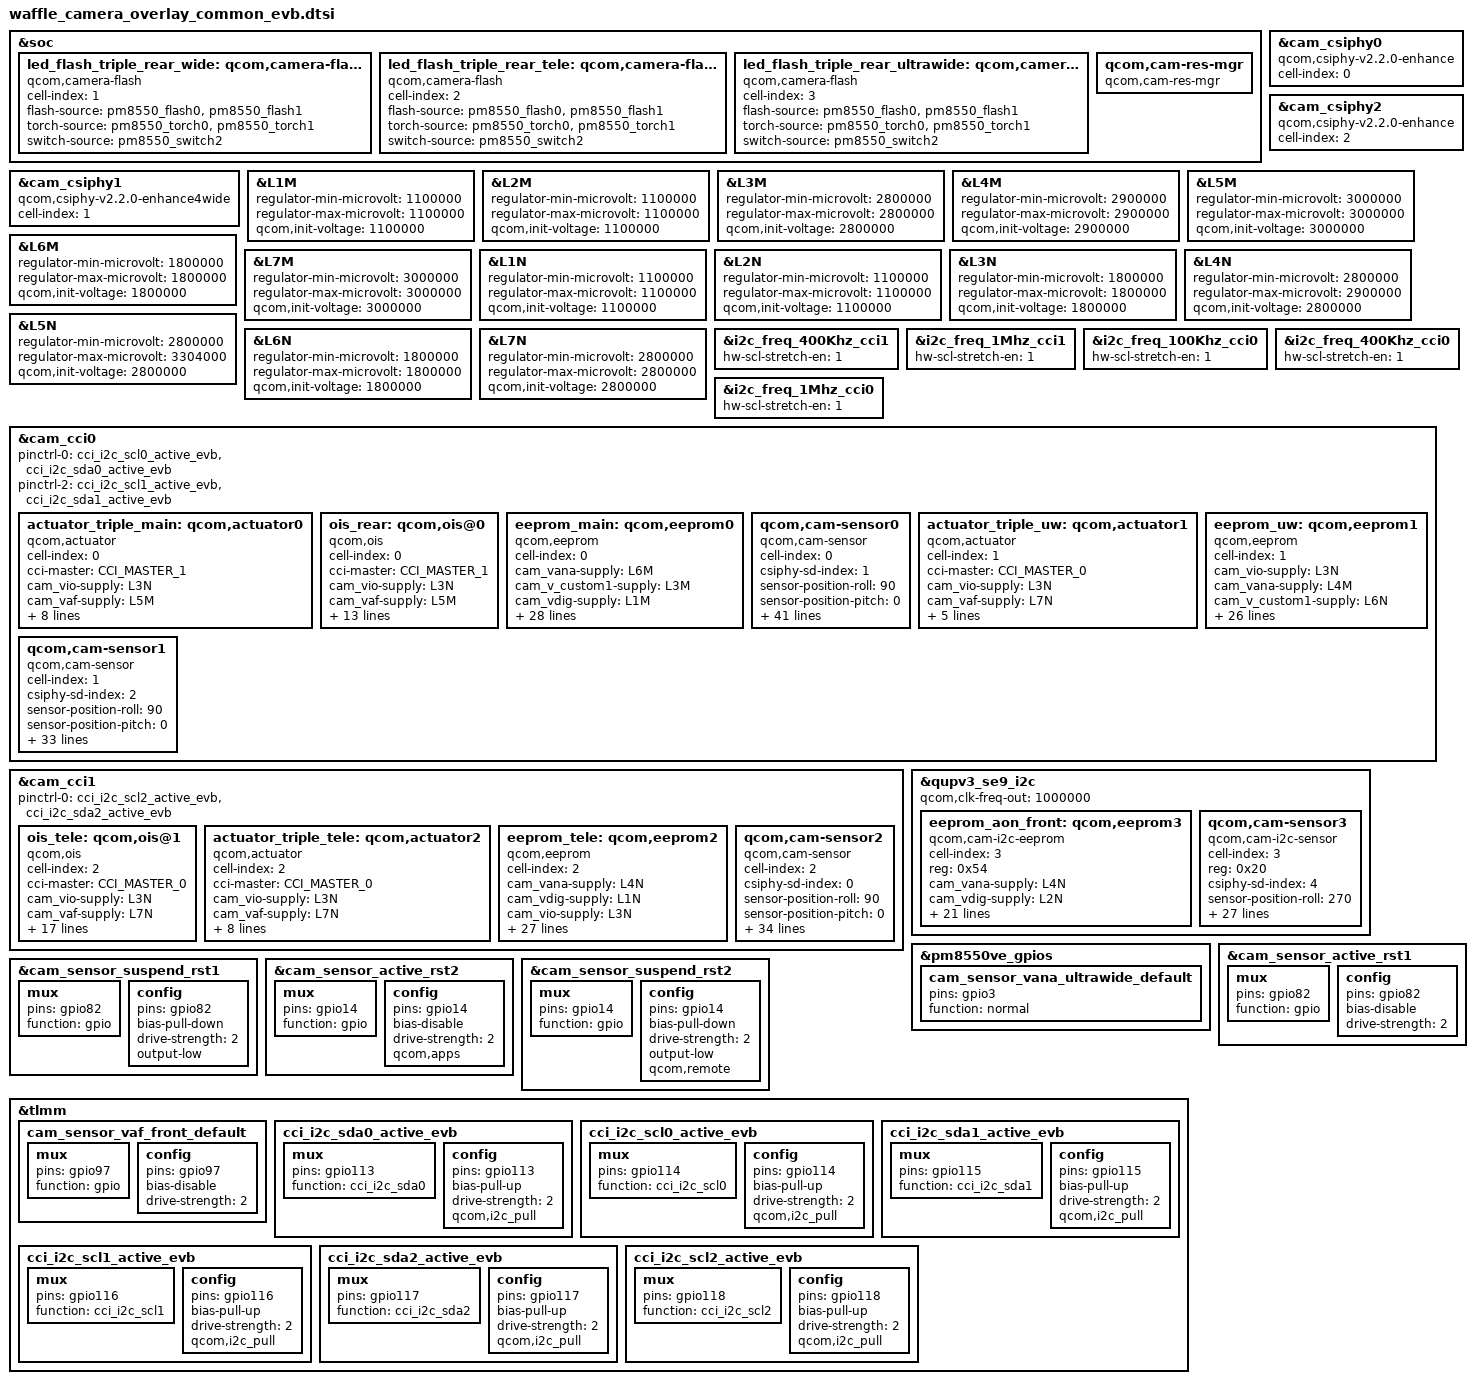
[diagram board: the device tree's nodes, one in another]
#include <dt-bindings/msm-camera.h>

&soc {
	led_flash_triple_rear_wide: qcom,camera-flash1 {
		cell-index = <1>;
		compatible = "qcom,camera-flash";
		flash-source = <&pm8550_flash0 &pm8550_flash1>;
		torch-source = <&pm8550_torch0 &pm8550_torch1>;
		switch-source = <&pm8550_switch2>;
		status = "ok";
	};

	led_flash_triple_rear_tele: qcom,camera-flash2 {
		cell-index = <2>;
		compatible = "qcom,camera-flash";
		flash-source = <&pm8550_flash0 &pm8550_flash1>;
		torch-source = <&pm8550_torch0 &pm8550_torch1>;
		switch-source = <&pm8550_switch2>;
		status = "ok";
	};

	led_flash_triple_rear_ultrawide: qcom,camera-flash3 {
		cell-index = <3>;
		compatible = "qcom,camera-flash";
		flash-source = <&pm8550_flash0 &pm8550_flash1>;
		torch-source = <&pm8550_torch0 &pm8550_torch1>;
		switch-source = <&pm8550_switch2>;
		status = "ok";
	};

	qcom,cam-res-mgr {
		compatible = "qcom,cam-res-mgr";
		status = "ok";
	};

};
&cam_csiphy0{
	cell-index = <0>;
	compatible = "qcom,csiphy-v2.2.0-enhance", "qcom,csiphy";
};
&cam_csiphy1{
	cell-index = <1>;
	compatible = "qcom,csiphy-v2.2.0-enhance4wide", "qcom,csiphy";
};
&cam_csiphy2{
	cell-index = <2>;
	compatible = "qcom,csiphy-v2.2.0-enhance", "qcom,csiphy";
};
&L1M {
  regulator-min-microvolt = <1100000>;
  regulator-max-microvolt = <1100000>;
  qcom,init-voltage = <1100000>;
};
&L2M {
  regulator-min-microvolt = <1100000>;
  regulator-max-microvolt = <1100000>;
  qcom,init-voltage = <1100000>;
};
&L3M {
  regulator-min-microvolt = <2800000>;
  regulator-max-microvolt = <2800000>;
  qcom,init-voltage = <2800000>;
};
&L4M {
  regulator-min-microvolt = <2900000>;
  regulator-max-microvolt = <2900000>;
  qcom,init-voltage = <2900000>;
};
&L5M {
  regulator-min-microvolt = <3000000>;
  regulator-max-microvolt = <3000000>;
  qcom,init-voltage = <3000000>;
};
&L6M {
  regulator-min-microvolt = <1800000>;
  regulator-max-microvolt = <1800000>;
  qcom,init-voltage = <1800000>;
};
&L7M {
  regulator-min-microvolt = <3000000>;
  regulator-max-microvolt = <3000000>;
  qcom,init-voltage = <3000000>;
};
&L1N {
  regulator-min-microvolt = <1100000>;
  regulator-max-microvolt = <1100000>;
  qcom,init-voltage = <1100000>;
};
&L2N {
  regulator-min-microvolt = <1100000>;
  regulator-max-microvolt = <1100000>;
  qcom,init-voltage = <1100000>;
};
&L3N {
  regulator-min-microvolt = <1800000>;
  regulator-max-microvolt = <1800000>;
  qcom,init-voltage = <1800000>;
};
&L4N {
  regulator-min-microvolt = <2800000>;
  regulator-max-microvolt = <2900000>;
  qcom,init-voltage = <2800000>;
};
&L5N {
  regulator-min-microvolt = <2800000>;
  regulator-max-microvolt = <3304000>;
  qcom,init-voltage = <2800000>;
};
&L6N{
  regulator-min-microvolt = <1800000>;
  regulator-max-microvolt = <1800000>;
  qcom,init-voltage = <1800000>;
};
&L7N{
  regulator-min-microvolt = <2800000>;
  regulator-max-microvolt = <2800000>;
  qcom,init-voltage = <2800000>;
};

&i2c_freq_400Khz_cci1 {
    hw-scl-stretch-en = <1>;
};

&i2c_freq_1Mhz_cci1 {
    hw-scl-stretch-en = <1>;
};

&i2c_freq_100Khz_cci0 {
    hw-scl-stretch-en = <1>;
};

&i2c_freq_400Khz_cci0 {
    hw-scl-stretch-en = <1>;
};

&i2c_freq_1Mhz_cci0 {
    hw-scl-stretch-en = <1>;
};

&cam_cci0 {
	pinctrl-0 = <&cci_i2c_scl0_active_evb &cci_i2c_sda0_active_evb>;
	pinctrl-2 = <&cci_i2c_scl1_active_evb &cci_i2c_sda1_active_evb>;
	actuator_triple_main: qcom,actuator0 {
		cell-index = <0>;
		compatible = "qcom,actuator";
		cci-master = <CCI_MASTER_1>;
		cam_vio-supply = <&L3N>;
		cam_vaf-supply = <&L5M>;
		regulator-names = "cam_vio", "cam_vaf";
		rgltr-cntrl-support;
		rgltr-min-voltage = <1800000 3000000>;
		rgltr-max-voltage = <1800000 3000000>;
		rgltr-load-current = <600000 300000>;
		reactive-ctrl-support;
		//                       reg_addr   addr_type   reg_data    data_type   delay       data_mask
		reactive-reg-setting = < 0x02       1           0x00        1           2800        0x00 >;
		actuator,name = "ak7316";
		status = "ok";
	};

	ois_rear: qcom,ois@0{
		cell-index = <0>;
		compatible = "qcom,ois";
		cci-master = <CCI_MASTER_1>;
		cam_vio-supply = <&L3N>;
		cam_vaf-supply = <&L5M>;
		cam_v_custom2-supply = <&L7M>;
		regulator-names = "cam_vio", "cam_vaf","cam_v_custom2";
		rgltr-cntrl-support;
		rgltr-min-voltage = <1800000 3000000 3000000>;
		rgltr-max-voltage = <1800000 3000000 3000000>;
		rgltr-load-current = <600000 300000 300000>;
		ois_gyro,position=<3>;
		ois_gyro,type=<3>;
		ois,type=<0>;
		//ois,name="bu63169";//??
		ois_module,vendor=<1>;
		ois_actuator,vednor=<2>;
		ois,fw=<1>;
		status = "ok";
	};

	eeprom_main: qcom,eeprom0 {
		cell-index = <0>;
		compatible = "qcom,eeprom";
		cam_vana-supply = <&L6M>;
		cam_v_custom1-supply = <&L3M>;
		cam_vdig-supply = <&L1M>;
		cam_vio-supply = <&L3N>;
		cam_vaf-supply = <&L5M>;
		cam_v_custom2-supply = <&L7M>;
		cam_clk-supply = <&cam_cc_titan_top_gdsc>;
		regulator-names = "cam_vana", "cam_v_custom1", "cam_vdig", "cam_vio", "cam_vaf", "cam_v_custom2",
		                  "cam_clk";
		rgltr-cntrl-support;
		rgltr-min-voltage = <1800000 2800000 1100000 1800000 3000000 3000000 0>;
		rgltr-max-voltage = <1800000 2800000 1100000 1800000 3000000 3000000 0>;
		rgltr-load-current = <300000 600000 1200000 600000 300000 300000 0>;
		gpio-no-mux = <0>;
		pinctrl-names = "cam_default", "cam_suspend";
		pinctrl-0 = <&cam_sensor_mclk1_active
			&cam_sensor_active_rst1>;
		pinctrl-1 = <&cam_sensor_mclk1_suspend
			&cam_sensor_suspend_rst1>;
		gpios = <&tlmm 101 0>,
			<&tlmm 82 0>;
		gpio-reset = <1>;
		gpio-req-tbl-num = <0 1>;
		gpio-req-tbl-flags = <1 0>;
		gpio-req-tbl-label = "CAMIF_MCLK1",
					"CAM_RESET1";
		cci-master = <CCI_MASTER_1>;
		clocks = <&camcc CAM_CC_MCLK1_CLK>;
		clock-names = "cam_clk";
		clock-cntl-level = "nominal";
		clock-rates = <19200000>;
		status = "ok";
	};

    //main camera
	qcom,cam-sensor0 {
		cell-index = <0>;
		compatible = "qcom,cam-sensor";
		csiphy-sd-index = <1>;
		sensor-position-roll = <90>;
		sensor-position-pitch = <0>;
		sensor-position-yaw = <180>;
		eeprom-src = <&eeprom_main>;
		actuator-src = <&actuator_triple_main>;
		ois-src = <&ois_rear>;
		led-flash-src = <&led_flash_triple_rear_wide>;
		cam_vana-supply = <&L6M>;
		cam_v_custom1-supply = <&L3M>;
		cam_vdig-supply = <&L1M>;
		cam_vio-supply = <&L3N>;
		cam_vaf-supply = <&L5M>;
		cam_v_custom2-supply = <&L7M>;
		cam_clk-supply = <&cam_cc_titan_top_gdsc>;
		regulator-names = "cam_vana", "cam_v_custom1", "cam_vdig", "cam_vio", "cam_vaf", "cam_v_custom2",
		                  "cam_clk";
		rgltr-cntrl-support;
		rgltr-min-voltage = <1800000 2800000 1100000 1800000 3000000 3000000 0>;
		rgltr-max-voltage = <1800000 2800000 1100000 1800000 3000000 3000000 0>;
		rgltr-load-current = <300000 600000 1200000 600000 300000 300000 0>;
		gpio-no-mux = <0>;
		pinctrl-names = "cam_default", "cam_suspend";
		pinctrl-0 = <&cam_sensor_mclk1_active
			&cam_sensor_active_rst1>;
		pinctrl-1 = <&cam_sensor_mclk1_suspend
			&cam_sensor_suspend_rst1>;
		gpios = <&tlmm 101 0>,
			<&tlmm 82 0>;
		gpio-reset = <1>;
		gpio-req-tbl-num = <0 1>;
		gpio-req-tbl-flags = <1 0>;
		gpio-req-tbl-label = "CAMIF_MCLK1",
					"CAM_RESET1";
		cci-master = <CCI_MASTER_1>;
		clocks = <&camcc CAM_CC_MCLK1_CLK>;
		clock-names = "cam_clk";
		clock-cntl-level = "nominal";
		clock-rates = <19200000>;
		enable_qsc_write_in_advance = <1>;
		qsc_reg_addr = <0x1E30>;
		eeprom_slave_addr = <0xA0>;
		qsc_data_size = <3072>;
		write_qsc_addr = <0xC000>;
		status = "ok";
	};

	actuator_triple_uw: qcom,actuator1 {
		cell-index = <1>;
		compatible = "qcom,actuator";
		cci-master = <CCI_MASTER_0>;
		cam_vio-supply = <&L3N>;
		cam_vaf-supply = <&L7N>;
		regulator-names = "cam_vio","cam_vaf";
		rgltr-cntrl-support;
		rgltr-min-voltage = <1800000 2800000>;
		rgltr-max-voltage = <1800000 2800000>;
		rgltr-load-current = <600000 600000>;
		status = "ok";
	};

	eeprom_uw: qcom,eeprom1 {
		cell-index = <1>;
		compatible = "qcom,eeprom";
		cam_vio-supply = <&L3N>;
		cam_vana-supply = <&L4M>;
		cam_v_custom1-supply = <&L6N>;
		cam_vaf-supply = <&L7N>;
		cam_vdig-supply = <&L2M>;
		cam_clk-supply = <&cam_cc_titan_top_gdsc>;
		regulator-names = "cam_vio", "cam_vana","cam_v_custom1",
			"cam_vaf","cam_vdig", "cam_clk";
		rgltr-cntrl-support;
		rgltr-min-voltage = <1800000 2900000  1800000 2800000 1100000 0>;
		rgltr-max-voltage = <1800000 2900000  1800000 2800000 1100000 0>;
		rgltr-load-current = <600000 300000 600000  600000 1200000 0>;
		gpio-no-mux = <0>;
		pinctrl-names = "cam_default", "cam_suspend";
		pinctrl-0 = <&cam_sensor_mclk2_active
				 &cam_sensor_active_rst2>;
		pinctrl-1 = <&cam_sensor_mclk2_suspend
				 &cam_sensor_suspend_rst2>;
		gpios = <&tlmm 102 0>,
			<&tlmm 14 0>;
		gpio-reset = <1>;
		gpio-req-tbl-num = <0 1>;
		gpio-req-tbl-flags = <1 0>;
		gpio-req-tbl-label = "CAMIF_MCLK2",
					"CAM_RESET2";
		cci-master = <CCI_MASTER_0>;
		clocks = <&camcc CAM_CC_MCLK2_CLK>;
		clock-names = "cam_clk";
		clock-cntl-level = "nominal";
		clock-rates = <19200000>;
		status = "ok";
	};

    //wide camera
	qcom,cam-sensor1 {
		cell-index = <1>;
		compatible = "qcom,cam-sensor";
		csiphy-sd-index = <2>;
		sensor-position-roll = <90>;
		sensor-position-pitch = <0>;
		sensor-position-yaw = <180>;
		eeprom-src = <&eeprom_uw>;
		actuator-src = <&actuator_triple_uw>;
		led-flash-src = <&led_flash_triple_rear_ultrawide>;
		cam_vio-supply = <&L3N>;
		cam_vana-supply = <&L4M>;
		cam_v_custom1-supply = <&L6N>;
		cam_vaf-supply = <&L7N>;
		cam_vdig-supply = <&L2M>;
		cam_clk-supply = <&cam_cc_titan_top_gdsc>;
		regulator-names = "cam_vio", "cam_vana","cam_v_custom1",
			"cam_vaf","cam_vdig", "cam_clk";
		rgltr-cntrl-support;
		rgltr-min-voltage = <1800000 2900000  1800000 2800000 1100000 0>;
		rgltr-max-voltage = <1800000 2900000  1800000 2800000 1100000 0>;
		rgltr-load-current = <600000 300000 600000  600000 1200000 0>;
		gpio-no-mux = <0>;
		pinctrl-names = "cam_default", "cam_suspend";
		pinctrl-0 = <&cam_sensor_mclk2_active
				 &cam_sensor_active_rst2>;
		pinctrl-1 = <&cam_sensor_mclk2_suspend
				 &cam_sensor_suspend_rst2>;
		gpios = <&tlmm 102 0>,
			<&tlmm 14 0>;
		gpio-reset = <1>;
		gpio-req-tbl-num = <0 1>;
		gpio-req-tbl-flags = <1 0>;
		gpio-req-tbl-label = "CAMIF_MCLK2",
					"CAM_RESET2";
		cci-master = <CCI_MASTER_0>;
		clocks = <&camcc CAM_CC_MCLK2_CLK>;
		clock-names = "cam_clk";
		clock-cntl-level = "nominal";
		clock-rates = <19200000>;
		status = "ok";
	};
};
&cam_cci1 {
	pinctrl-0 = <&cci_i2c_scl2_active_evb &cci_i2c_sda2_active_evb>;
	ois_tele: qcom,ois@1{
		cell-index = <2>;
		compatible = "qcom,ois";
		cci-master = <CCI_MASTER_0>;
		cam_vio-supply = <&L3N>;
		cam_vaf-supply = <&L7N>;
		cam_v_custom1-supply = <&L5N>;
		regulator-names = "cam_vio", "cam_vaf","cam_v_custom1";
		rgltr-cntrl-support;
		rgltr-min-voltage = <1800000 2800000 2800000>;
		rgltr-max-voltage = <1800000 2800000 2800000>;
		rgltr-load-current = <600000 600000 300000>;
		ois_gyro,position=<3>;
		ois_gyro,type=<0>;
		ois,type=<1>;
		ois,name="sem1217s";
		ois_module,vendor=<0>;
		ois_actuator,vednor=<7>;
		ois,fw=<1>;
		download,fw=<1>;
		ois_eis_function = <6>;
		actuator_ois_eeprom_merge = <1>;
		status = "ok";
	};

	actuator_triple_tele: qcom,actuator2{
		cell-index = <2>;
		compatible = "qcom,actuator";
		cci-master = <CCI_MASTER_0>;
		cam_vio-supply = <&L3N>;
		cam_vaf-supply = <&L7N>;
		cam_v_custom1-supply = <&L5N>;
		regulator-names = "cam_vio", "cam_vaf","cam_v_custom1";
		rgltr-cntrl-support;
		rgltr-min-voltage = <1800000 2800000 2800000>;
		rgltr-max-voltage = <1800000 2800000 2800000>;
		rgltr-load-current = <600000 600000 300000>;
		actuator,name = "sem1217s";
		status = "ok";
	};
	eeprom_tele: qcom,eeprom2 {
		cell-index = <2>;
		compatible = "qcom,eeprom";
		cam_vana-supply = <&L4N>;
		cam_vdig-supply = <&L1N>;
		cam_vio-supply = <&L3N>;
		cam_vaf-supply = <&L7N>;
        cam_v_custom1-supply = <&L5N>;
		cam_clk-supply = <&cam_cc_titan_top_gdsc>;
		regulator-names = "cam_vana", "cam_vdig", "cam_vio", "cam_vaf",
		                  "cam_v_custom1","cam_clk";
		rgltr-cntrl-support;
		rgltr-min-voltage = <2800000 1100000 1800000 2800000 2800000 0>;
		rgltr-max-voltage = <2800000 1100000 1800000 2800000 2800000 0>;
		rgltr-load-current = <300000 1200000 600000 600000 600000 0>;
		gpio-no-mux = <0>;
		pinctrl-names = "cam_default", "cam_suspend";
		pinctrl-0 = <&cam_sensor_mclk3_active
				 &cam_sensor_active_rst3>;
		pinctrl-1 = <&cam_sensor_mclk3_suspend
				 &cam_sensor_suspend_rst3>;
		gpios = <&tlmm 103 0>,
			<&tlmm 109 0>;
		gpio-reset = <1>;
		gpio-req-tbl-num = <0 1>;
		gpio-req-tbl-flags = <1 0>;
		gpio-req-tbl-label = "CAMIF_MCLK3",
					"CAM_RESET3";
		cci-master = <CCI_MASTER_0>;
		clocks = <&camcc CAM_CC_MCLK3_CLK>;
		clock-names = "cam_clk";
		clock-cntl-level = "nominal";
		clock-rates = <19200000>;
		actuator_ois_eeprom_merge = <1>;
		status = "ok";
	};
    //tele
	qcom,cam-sensor2 {
		cell-index = <2>;
		compatible = "qcom,cam-sensor";
		csiphy-sd-index = <0>;
		sensor-position-roll = <90>;
		sensor-position-pitch = <0>;
		sensor-position-yaw = <180>;
		ois-src = <&ois_tele>;
		eeprom-src = <&eeprom_tele>;
		actuator-src = <&actuator_triple_tele>;
		led-flash-src = <&led_flash_triple_rear_tele>;
		cam_vana-supply = <&L4N>;
		cam_vdig-supply = <&L1N>;
		cam_vio-supply = <&L3N>;
		cam_vaf-supply = <&L7N>;
		cam_v_custom1-supply = <&L5N>;
		cam_clk-supply = <&cam_cc_titan_top_gdsc>;
		regulator-names = "cam_vana", "cam_vdig", "cam_vio", "cam_vaf",
		                  "cam_v_custom1","cam_clk";
		rgltr-cntrl-support;
		rgltr-min-voltage = <2800000 1100000 1800000 2800000 2800000 0>;
		rgltr-max-voltage = <2800000 1100000 1800000 2800000 2800000 0>;
		rgltr-load-current = <300000 1200000 600000 600000 600000 0>;
		gpio-no-mux = <0>;
		pinctrl-names = "cam_default", "cam_suspend";
		pinctrl-0 = <&cam_sensor_mclk3_active
				 &cam_sensor_active_rst3>;
		pinctrl-1 = <&cam_sensor_mclk3_suspend
				 &cam_sensor_suspend_rst3>;
		gpios = <&tlmm 103 0>,
			<&tlmm 109 0>;
		gpio-reset = <1>;
		gpio-req-tbl-num = <0 1>;
		gpio-req-tbl-flags = <1 0>;
		gpio-req-tbl-label = "CAMIF_MCLK3",
					"CAM_RESET3";
		cci-master = <CCI_MASTER_0>;
		clocks = <&camcc CAM_CC_MCLK3_CLK>;
		clock-names = "cam_clk";
		clock-cntl-level = "nominal";
		clock-rates = <19200000>;
		status = "ok";
	};

};
&qupv3_se9_i2c {
    status = "ok";
    qcom,clk-freq-out = <1000000>;
	eeprom_aon_front: qcom,eeprom3 {
		cell-index = <3>;
		reg = <0x54>;
		compatible = "qcom,cam-i2c-eeprom";
		cam_vana-supply = <&L4N>;
		cam_vdig-supply = <&L2N>;
		cam_vio-supply = <&L3N>;
		cam_clk-supply = <&cam_cc_titan_top_gdsc>;
		regulator-names = "cam_vana", "cam_vdig", "cam_vio", "cam_clk";
		rgltr-cntrl-support;
		rgltr-min-voltage = <2800000 1100000 1800000 0>;
		rgltr-max-voltage = <2800000 1100000 1800000 0>;
		rgltr-load-current = <300000 1200000 600000 0>;
		gpio-no-mux = <0>;
		pinctrl-names = "cam_default", "cam_suspend";
		pinctrl-0 = <&cam_sensor_mclk4_active
				 &cam_sensor_active_rst4>;
		pinctrl-1 = <&cam_sensor_mclk4_suspend
				 &cam_sensor_suspend_rst4>;
		gpios = <&tlmm 104 0>,
			<&tlmm 7 0>;
		gpio-reset = <1>;
		gpio-req-tbl-num = <0 1>;
		gpio-req-tbl-flags = <1 0>;
		gpio-req-tbl-label = "CAMIF_MCLK4",
					"CAM_RESET4";
		clocks = <&camcc CAM_CC_MCLK4_CLK>;
		clock-names = "cam_clk";
		clock-cntl-level = "nominal";
		clock-rates = <19200000>;
		status = "ok";
	};

	qcom,cam-sensor3 {
		cell-index = <3>;
		reg = <0x20>;
		compatible =  "qcom,cam-i2c-sensor";
		csiphy-sd-index = <4>;
		sensor-position-roll = <270>;
		sensor-position-pitch = <0>;
		sensor-position-yaw = <180>;
		eeprom-src = <&eeprom_aon_front>;
		cam_vana-supply = <&L4N>;
		cam_vdig-supply = <&L2N>;
		cam_vio-supply = <&L3N>;
		cam_clk-supply = <&cam_cc_titan_top_gdsc>;
		regulator-names = "cam_vana", "cam_vdig", "cam_vio", "cam_clk";
		rgltr-cntrl-support;
		aon-camera-id = <AON_CAM1>;
		rgltr-min-voltage = <2800000 1100000 1800000 0>;
		rgltr-max-voltage = <2800000 1100000 1800000 0>;
		rgltr-load-current = <300000 1200000 600000 0>;
		gpio-no-mux = <0>;
		pinctrl-names = "cam_default", "cam_suspend";
		pinctrl-0 = <&cam_sensor_mclk4_active
				 &cam_sensor_active_rst4>;
		pinctrl-1 = <&cam_sensor_mclk4_suspend
				 &cam_sensor_suspend_rst4>;
		gpios = <&tlmm 104 0>,
			<&tlmm 7 0>;
		gpio-reset = <1>;
		gpio-req-tbl-num = <0 1>;
		gpio-req-tbl-flags = <1 0>;
		gpio-req-tbl-label = "CAMIF_MCLK4",
					"CAM_RESET4";
		clocks = <&camcc CAM_CC_MCLK4_CLK>;
		clock-names = "cam_clk";
		clock-cntl-level = "nominal";
		clock-rates = <19200000>;
		status = "ok";
	};
};
&pm8550ve_gpios {
	cam_sensor_vana_ultrawide_default: cam_sensor_vana_ultrawide_default {
		pins = "gpio3";
		function = "normal";
	};
};
&cam_sensor_active_rst1 {
		mux {
			pins = "gpio82";
			function = "gpio";
		};

		config {
			pins = "gpio82";
			bias-disable; /* No PULL */
			drive-strength = <2>; /* 2 MA */
		};
	};

&cam_sensor_suspend_rst1 {
	mux {
		pins = "gpio82";
		function = "gpio";
	};

	config {
		pins = "gpio82";
		bias-pull-down; /* PULL DOWN */
		drive-strength = <2>; /* 2 MA */
		output-low;
	};
};

&cam_sensor_active_rst2 {
	mux {
		pins = "gpio14";
		function = "gpio";
	};

	config {
		pins = "gpio14";
		bias-disable; /* No PULL */
		drive-strength = <2>; /* 2 MA */
		qcom,apps;
	};
};

&cam_sensor_suspend_rst2 {
	mux {
		pins = "gpio14";
		function = "gpio";
	};

	config {
		pins = "gpio14";
		bias-pull-down; /* PULL DOWN */
		drive-strength = <2>; /* 2 MA */
		output-low;
		qcom,remote;
	};
};
&tlmm {
	cam_sensor_vaf_front_default: cam_sensor_vaf_front_default {
		/*  VIO LDO */
		mux {
			pins = "gpio97";
			function = "gpio";
		};

		config {
			pins = "gpio97";
			bias-disable; /* No PULL */
			drive-strength = <2>; /* 2 MA */
		};
	};
	cci_i2c_sda0_active_evb: cci_i2c_sda0_active_evb {
		mux {
			/* CLK, DATA */
			pins = "gpio113";
			function = "cci_i2c_sda0";
		};

		config {
			pins = "gpio113";
			bias-pull-up; /* PULL UP*/
			drive-strength = <2>; /* 2 MA */
			qcom,i2c_pull;
		};
	};
	cci_i2c_scl0_active_evb: cci_i2c_scl0_active_evb {
		mux {
			/* CLK, DATA */
			pins = "gpio114";
			function = "cci_i2c_scl0";
		};

		config {
			pins = "gpio114";
			bias-pull-up; /* PULL UP*/
			drive-strength = <2>; /* 2 MA */
			qcom,i2c_pull;
		};
	};
	cci_i2c_sda1_active_evb: cci_i2c_sda1_active_evb {
		mux {
			/* CLK, DATA */
			pins = "gpio115";
			function = "cci_i2c_sda1";
		};

		config {
			pins = "gpio115";
			bias-pull-up; /* PULL UP*/
			drive-strength = <2>; /* 2 MA */
			qcom,i2c_pull;
		};
	};
	cci_i2c_scl1_active_evb: cci_i2c_scl1_active_evb {
		mux {
			/* CLK, DATA */
			pins = "gpio116";
			function = "cci_i2c_scl1";
		};

		config {
			pins = "gpio116";
			bias-pull-up; /* PULL UP*/
			drive-strength = <2>; /* 2 MA */
			qcom,i2c_pull;
		};
	};
	cci_i2c_sda2_active_evb: cci_i2c_sda2_active_evb {
		mux {
			/* CLK, DATA */
			pins = "gpio117";
			function = "cci_i2c_sda2";
		};

		config {
			pins = "gpio117";
			bias-pull-up; /* PULL UP*/
			drive-strength = <2>; /* 2 MA */
			qcom,i2c_pull;
		};
	};
	cci_i2c_scl2_active_evb: cci_i2c_scl2_active_evb {
		mux {
			/* CLK, DATA */
			pins = "gpio118";
			function = "cci_i2c_scl2";
		};

		config {
			pins = "gpio118";
			bias-pull-up; /* PULL UP*/
			drive-strength = <2>; /* 2 MA */
			qcom,i2c_pull;
		};
	};
};
